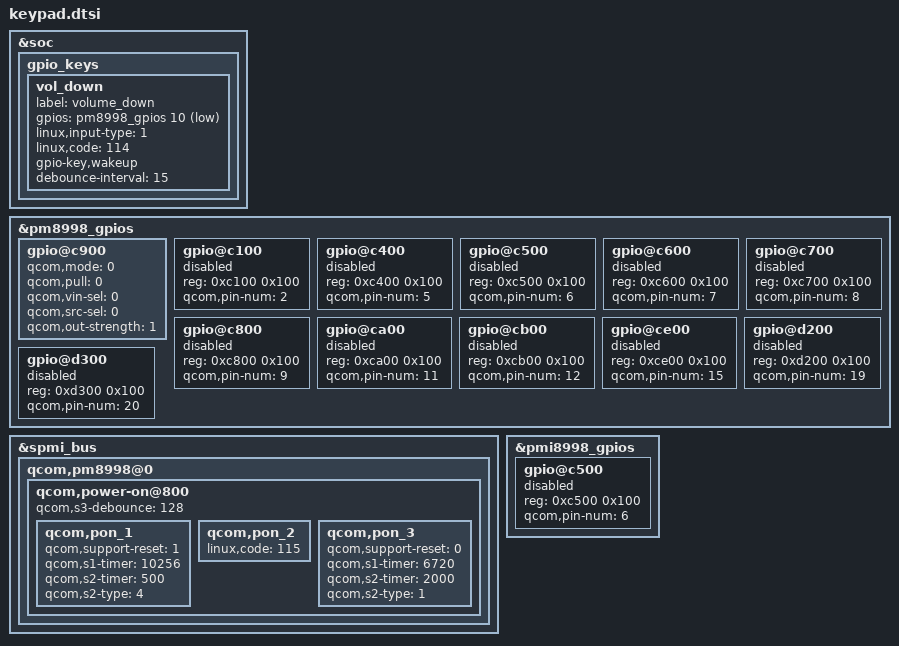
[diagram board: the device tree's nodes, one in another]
&soc {
	gpio_keys {
		/delete-node/ vol_up;
		vol_down {
			label = "volume_down";
			gpios = <&pm8998_gpios 10 0x1>;
			linux,input-type = <1>;
			linux,code = <114>;
			gpio-key,wakeup;
			debounce-interval = <15>;
		};
		/delete-node/ home;
		/delete-node/ cam_snapshot;
		/delete-node/ cam_focus;
	};
};
&pm8998_gpios {
	/* GPIO 10 for Vol- Key */
	gpio@c900 {
		status = "okay";
		qcom,mode = <0>;
		qcom,pull = <0>;
		qcom,vin-sel = <0>;
		qcom,src-sel = <0>;
		qcom,out-strength = <1>;
	};
};

&spmi_bus {
	qcom,pm8998@0 {
		qcom,power-on@800 {
			qcom,s3-debounce = <128>;
			qcom,pon_1 {
				qcom,support-reset = <1>;
				/* RESET TRIGGER TIME: S1 + S2 = 10756ms */
				qcom,s1-timer = <10256>;
				qcom,s2-timer = <500>;
				/* RESET TYPE: SHUTDOWN(4) */
				qcom,s2-type = <4>;
			};
			/* PON: RESIN */
			qcom,pon_2 {
				linux,code = <115>;
			};
			qcom,pon_3 {
				qcom,support-reset = <0>;
				/* RESET TRIGGER TIME: S1 + S2 = 8720ms */
				qcom,s1-timer = <6720>;
				qcom,s2-timer = <2000>;
				/* RESET TYPE: WARM(1) */
				qcom,s2-type = <1>;
			};
		};
	};
};

/* Remove QCT default settings of our PM8998 unused GPIO */
&pm8998_gpios {
			/delete-node/ gpio@c100; /* GPIO 2 */
			/delete-node/ gpio@c400; /* GPIO 5 */
			/delete-node/ gpio@c500; /* GPIO 6 */
			/delete-node/ gpio@c600; /* GPIO 7 */
			/delete-node/ gpio@c700; /* GPIO 8 */
			/delete-node/ gpio@c800; /* GPIO 9 */
			/delete-node/ gpio@ca00; /* GPIO 11 */
			/delete-node/ gpio@cb00; /* GPIO 12 */
			/delete-node/ gpio@ce00; /* GPIO 15 */
			/delete-node/ gpio@d200; /* GPIO 19 */
			/delete-node/ gpio@d300; /* GPIO 20 */

			gpio@c100 {
				reg = <0xc100 0x100>;
				qcom,pin-num = <2>;
				status = "disabled";
			};

			gpio@c400 {
				reg = <0xc400 0x100>;
				qcom,pin-num = <5>;
				status = "disabled";
			};

			gpio@c500 {
				reg = <0xc500 0x100>;
				qcom,pin-num = <6>;
				status = "disabled";
			};

			gpio@c600 {
				reg = <0xc600 0x100>;
				qcom,pin-num = <7>;
				status = "disabled";
			};

			gpio@c700 {
				reg = <0xc700 0x100>;
				qcom,pin-num = <8>;
				status = "disabled";
			};

			gpio@c800 {
				reg = <0xc800 0x100>;
				qcom,pin-num = <9>;
				status = "disabled";
			};

			gpio@ca00 {
				reg = <0xca00 0x100>;
				qcom,pin-num = <11>;
				status = "disabled";
			};

			gpio@cb00 {
				reg = <0xcb00 0x100>;
				qcom,pin-num = <12>;
				status = "disabled";
			};

			gpio@ce00 {
				reg = <0xce00 0x100>;
				qcom,pin-num = <15>;
				status = "disabled";
			};

			gpio@d200 {
				reg = <0xd200 0x100>;
				qcom,pin-num = <19>;
				status = "disabled";
			};

			gpio@d300 {
				reg = <0xd300 0x100>;
				qcom,pin-num = <20>;
				status = "disabled";
			};
};

/* Remove QCT default settings of our PMI8998 unused GPIO */
&pmi8998_gpios {
			/delete-node/ gpio@c500; /* GPIO 6 */

			gpio@c500 {
				reg = <0xc500 0x100>;
				qcom,pin-num = <6>;
				status = "disabled";
			};
};
